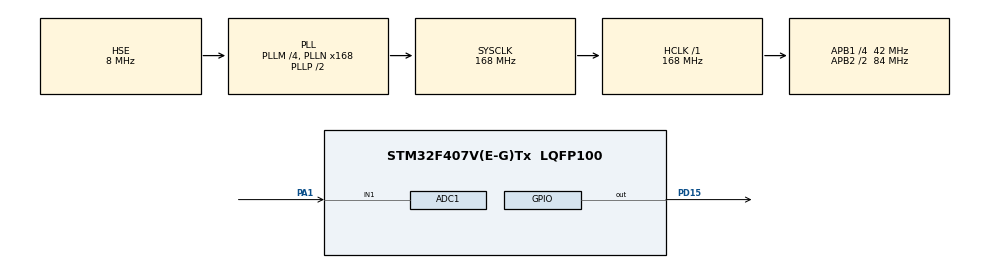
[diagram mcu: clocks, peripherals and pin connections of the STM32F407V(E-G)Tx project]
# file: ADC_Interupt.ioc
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ADC1.Channel-0\#ChannelRegularConversion=ADC_CHANNEL_1
ADC1.ContinuousConvMode=DISABLE
ADC1.ExternalTrigConv=ADC_EXTERNALTRIGCONV_T3_TRGO
ADC1.NbrOfConversionFlag=1
ADC1.Rank-0\#ChannelRegularConversion=1
ADC1.SamplingTime-0\#ChannelRegularConversion=ADC_SAMPLETIME_56CYCLES
ADC1.master=1
Mcu.Family=STM32F4
Mcu.Name=STM32F407V(E-G)Tx
Mcu.Package=LQFP100
NVIC.ADC_IRQn=true\:0\:0\:false\:false\:true\:true\:true\:true
NVIC.PriorityGroup=NVIC_PRIORITYGROUP_4
PA1.Signal=ADCx_IN1
PA13.Mode=Serial_Wire
PA13.Signal=SYS_JTMS-SWDIO
PA14.Mode=Serial_Wire
PA14.Signal=SYS_JTCK-SWCLK
PD15.GPIO_Speed=GPIO_SPEED_FREQ_MEDIUM
PD15.Signal=GPIO_Output
PH0-OSC_IN.Mode=HSE-External-Oscillator
PH0-OSC_IN.Signal=RCC_OSC_IN
PH1-OSC_OUT.Mode=HSE-External-Oscillator
PH1-OSC_OUT.Signal=RCC_OSC_OUT
ProjectManager.HeapSize=0x200
ProjectManager.StackSize=0x400
ProjectManager.TargetToolchain=STM32CubeIDE
RCC.48MHZClocksFreq_Value=84000000
RCC.AHBFreq_Value=168000000
RCC.APB1CLKDivider=RCC_HCLK_DIV4
RCC.APB1Freq_Value=42000000
RCC.APB1TimFreq_Value=84000000
RCC.APB2CLKDivider=RCC_HCLK_DIV2
RCC.APB2Freq_Value=84000000
RCC.APB2TimFreq_Value=168000000
RCC.CortexFreq_Value=168000000
RCC.HCLKFreq_Value=168000000
RCC.HSE_VALUE=8000000
RCC.HSI_VALUE=16000000
RCC.LSE_VALUE=32768
RCC.PLLM=4
RCC.PLLN=168
RCC.PLLSourceVirtual=RCC_PLLSOURCE_HSE
RCC.SYSCLKFreq_VALUE=168000000
RCC.SYSCLKSource=RCC_SYSCLKSOURCE_PLLCLK
RCC.VCOOutputFreq_Value=336000000
SH.ADCx_IN1.0=ADC1_IN1,IN1
TIM3.AutoReloadPreload=TIM_AUTORELOAD_PRELOAD_ENABLE
TIM3.Period=19
TIM3.Prescaler=83
TIM3.TIM_MasterOutputTrigger=TIM_TRGO_UPDATE
VP_TIM3_VS_ClockSourceINT.Mode=Internal
board=custom

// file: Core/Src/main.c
/* USER CODE BEGIN Header */
/**
  ******************************************************************************
  * @file           : main.c
  * @brief          : Main program body
  ******************************************************************************
  * @attention
  *
  * Copyright (c) 2022 STMicroelectronics.
  * All rights reserved.
  *
  * This software is licensed under terms that can be found in the LICENSE file
  * in the root directory of this software component.
  * If no LICENSE file comes with this software, it is provided AS-IS.
  *
  ******************************************************************************
  */
/* USER CODE END Header */
#include "main.h"

/* USER CODE BEGIN PD */
#define Size 256
/* USER CODE END PD */

ADC_HandleTypeDef hadc1;

TIM_HandleTypeDef htim3;

/* USER CODE BEGIN PV */
uint16_t ADCValue=0;
uint16_t buffer[Size];

/* USER CODE END PV */

void SystemClock_Config(void);
static void MX_GPIO_Init(void);
static void MX_ADC1_Init(void);
static void MX_TIM3_Init(void);

int main(void)
{

  /* MCU Configuration--------------------------------------------------------*/

  /* Reset of all peripherals, Initializes the Flash interface and the Systick. */
  HAL_Init();

  /* Configure the system clock */
  SystemClock_Config();

  /* Initialize all configured peripherals */
  MX_GPIO_Init();
  MX_ADC1_Init();
  MX_TIM3_Init();
  /* USER CODE BEGIN 2 */
  HAL_ADC_Start_IT(&hadc1);
  HAL_TIM_Base_Start(&htim3);
  /* USER CODE END 2 */

  /* Infinite loop */
  while (1)
  {

    /* USER CODE BEGIN 3 */
	//HAL_Delay(5);

  }
  /* USER CODE END 3 */
}

void SystemClock_Config(void)
{
  RCC_OscInitTypeDef RCC_OscInitStruct = {0};
  RCC_ClkInitTypeDef RCC_ClkInitStruct = {0};

  /** Configure the main internal regulator output voltage
  */
  __HAL_RCC_PWR_CLK_ENABLE();
  __HAL_PWR_VOLTAGESCALING_CONFIG(PWR_REGULATOR_VOLTAGE_SCALE1);

  /** Initializes the RCC Oscillators according to the specified parameters
  * in the RCC_OscInitTypeDef structure.
  */
  RCC_OscInitStruct.OscillatorType = RCC_OSCILLATORTYPE_HSE;
  RCC_OscInitStruct.HSEState = RCC_HSE_ON;
  RCC_OscInitStruct.PLL.PLLState = RCC_PLL_ON;
  RCC_OscInitStruct.PLL.PLLSource = RCC_PLLSOURCE_HSE;
  RCC_OscInitStruct.PLL.PLLM = 4;
  RCC_OscInitStruct.PLL.PLLN = 168;
  RCC_OscInitStruct.PLL.PLLP = RCC_PLLP_DIV2;
  RCC_OscInitStruct.PLL.PLLQ = 4;
  if (HAL_RCC_OscConfig(&RCC_OscInitStruct) != HAL_OK)
  {
    Error_Handler();
  }

  /** Initializes the CPU, AHB and APB buses clocks
  */
  RCC_ClkInitStruct.ClockType = RCC_CLOCKTYPE_HCLK|RCC_CLOCKTYPE_SYSCLK
                              |RCC_CLOCKTYPE_PCLK1|RCC_CLOCKTYPE_PCLK2;
  RCC_ClkInitStruct.SYSCLKSource = RCC_SYSCLKSOURCE_PLLCLK;
  RCC_ClkInitStruct.AHBCLKDivider = RCC_SYSCLK_DIV1;
  RCC_ClkInitStruct.APB1CLKDivider = RCC_HCLK_DIV4;
  RCC_ClkInitStruct.APB2CLKDivider = RCC_HCLK_DIV2;

  if (HAL_RCC_ClockConfig(&RCC_ClkInitStruct, FLASH_LATENCY_5) != HAL_OK)
  {
    Error_Handler();
  }
}

static void MX_ADC1_Init(void)
{

  ADC_ChannelConfTypeDef sConfig = {0};

  /** Configure the global features of the ADC (Clock, Resolution, Data Alignment and number of conversion)
  */
  hadc1.Instance = ADC1;
  hadc1.Init.ClockPrescaler = ADC_CLOCK_SYNC_PCLK_DIV4;
  hadc1.Init.Resolution = ADC_RESOLUTION_12B;
  hadc1.Init.ScanConvMode = DISABLE;
  hadc1.Init.ContinuousConvMode = DISABLE;
  hadc1.Init.DiscontinuousConvMode = DISABLE;
  hadc1.Init.ExternalTrigConvEdge = ADC_EXTERNALTRIGCONVEDGE_RISING;
  hadc1.Init.ExternalTrigConv = ADC_EXTERNALTRIGCONV_T3_TRGO;
  hadc1.Init.DataAlign = ADC_DATAALIGN_RIGHT;
  hadc1.Init.NbrOfConversion = 1;
  hadc1.Init.DMAContinuousRequests = DISABLE;
  hadc1.Init.EOCSelection = ADC_EOC_SINGLE_CONV;
  if (HAL_ADC_Init(&hadc1) != HAL_OK)
  {
    Error_Handler();
  }

  /** Configure for the selected ADC regular channel its corresponding rank in the sequencer and its sample time.
  */
  sConfig.Channel = ADC_CHANNEL_1;
  sConfig.Rank = 1;
  sConfig.SamplingTime = ADC_SAMPLETIME_56CYCLES;
  if (HAL_ADC_ConfigChannel(&hadc1, &sConfig) != HAL_OK)
  {
    Error_Handler();
  }

}

static void MX_TIM3_Init(void)
{

  TIM_ClockConfigTypeDef sClockSourceConfig = {0};
  TIM_MasterConfigTypeDef sMasterConfig = {0};

  htim3.Instance = TIM3;
  htim3.Init.Prescaler = 83;
  htim3.Init.CounterMode = TIM_COUNTERMODE_UP;
  htim3.Init.Period = 19;
  htim3.Init.ClockDivision = TIM_CLOCKDIVISION_DIV1;
  htim3.Init.AutoReloadPreload = TIM_AUTORELOAD_PRELOAD_ENABLE;
  if (HAL_TIM_Base_Init(&htim3) != HAL_OK)
  {
    Error_Handler();
  }
  sClockSourceConfig.ClockSource = TIM_CLOCKSOURCE_INTERNAL;
  if (HAL_TIM_ConfigClockSource(&htim3, &sClockSourceConfig) != HAL_OK)
  {
    Error_Handler();
  }
  sMasterConfig.MasterOutputTrigger = TIM_TRGO_UPDATE;
  sMasterConfig.MasterSlaveMode = TIM_MASTERSLAVEMODE_DISABLE;
  if (HAL_TIMEx_MasterConfigSynchronization(&htim3, &sMasterConfig) != HAL_OK)
  {
    Error_Handler();
  }

}

static void MX_GPIO_Init(void)
{
  GPIO_InitTypeDef GPIO_InitStruct = {0};

  /* GPIO Ports Clock Enable */
  __HAL_RCC_GPIOH_CLK_ENABLE();
  __HAL_RCC_GPIOA_CLK_ENABLE();
  __HAL_RCC_GPIOD_CLK_ENABLE();

  /*Configure GPIO pin Output Level */
  HAL_GPIO_WritePin(GPIOD, GPIO_PIN_15, GPIO_PIN_RESET);

  /*Configure GPIO pin : PD15 */
  GPIO_InitStruct.Pin = GPIO_PIN_15;
  GPIO_InitStruct.Mode = GPIO_MODE_OUTPUT_PP;
  GPIO_InitStruct.Pull = GPIO_NOPULL;
  GPIO_InitStruct.Speed = GPIO_SPEED_FREQ_MEDIUM;
  HAL_GPIO_Init(GPIOD, &GPIO_InitStruct);

}

/* USER CODE BEGIN 4 */
void HAL_ADC_ConvCpltCallback(ADC_HandleTypeDef* hadc)
{
	static uint8_t i=0;
	ADCValue=HAL_ADC_GetValue(&hadc1);
	buffer[i++]=HAL_ADC_GetValue(&hadc1);

}

/* USER CODE END 4 */

void Error_Handler(void)
{
  __disable_irq();
  while (1)
  {
  }
}
